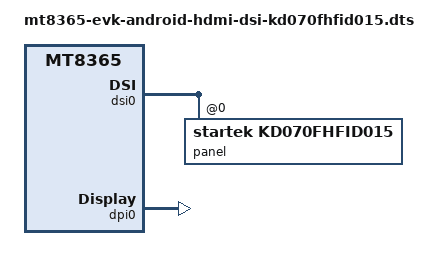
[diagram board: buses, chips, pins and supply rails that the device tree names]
// SPDX-License-Identifier: GPL-2.0
/*
 * Copyright (c) 2025 BayLibre, SAS.
 * Author: Esteban Blanc <eblanc@baylibre.com>
 */

/dts-v1/;
/plugin/;

#include "mt8365-evk-android.dtsi"

&dsi0 {
        panel@0 {
                compatible = "startek,kd070fhfid015";
                status = "okay";
        };
};

&dpi0 {
	status = "okay";
};

&ethernet {
	/*
	 * Ethernet and HDMI (DPI0) are sharing pins.
	 * Only one can be enabled at a time and require the physical switch
	 * SW2101 to be set on the desired position
	 */
	status = "disabled";
};
